# M2003 register map
File version: 1.0
Registers are 32-bit, read-write, reset 0x0 unless marked. A register's access mark holds for its fields unless they carry their own. Offsets are from the block's base; [hi:lo] are bit positions; {n}, {i} and the like mark numbered series; 'fields as' and 'values as' point back to an identical list.

## SYS — SYS Register Map
Base 0x40000000
0x00 SYS_PDID ro reset 0x200300 — Part Device Identification Number Register
  [31:0] PDID — Part Device Identification Number (Read Only). This register reflects device part number code. Software can read this register to identify which device is used.
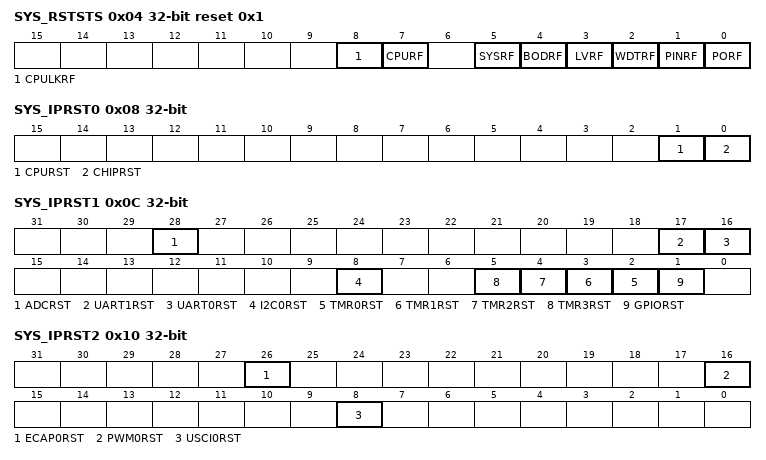
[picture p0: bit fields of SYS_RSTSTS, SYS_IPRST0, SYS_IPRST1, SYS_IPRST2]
0x04 SYS_RSTSTS reset 0x1 — System Reset Status Register
  [8] CPULKRF — CPU Lockup Reset Flag. The CPU Lockup reset flag is set by hardware if Cortex-M23 lockup happened. Note 1: Write 1 to clear this bit to 0. Note 2: When CPU lockup happened under ICE is connected, this flag will set to 1 but chip will not reset.
    0=No reset from CPU lockup happened; 1=The Cortex-M23 lockup happened and chip is reset
  [7] CPURF — CPU Reset Flag. The CPU reset flag is set by hardware if software writes CPURST (SYS_IPRST0[1]) 1 to reset the Cortex-M23 core and Flash Memory Controller (FMC). Note: Write 1 to clear this bit to 0.
    0=No reset from CPU; 1=The Cortex-M23 core and FMC are reset by software setting CPURST to 1
  [5] SYSRF — System Reset Flag. The system reset flag is set by the 'Reset Signal' from the Cortex-M23 core to indicate the previous reset source. Note: Write 1 to clear this bit to 0.
    0=No reset from the Cortex-M23; 1=The Cortex-M23 had issued the reset signal to reset the system by writing 1 to the bit SYSRESETREQ(AIRCR[2], Application Interrupt and Reset Control Register, address = 0xE000ED0C) in system control registers of Cortex-M23 core
  [4] BODRF — BOD Reset Flag. The BOD reset flag is set by the 'Reset Signal' from the Brown-out Detector to indicate the previous reset source, and BOD reset flag is not set in SPD mode when BOD reset occur. Note: Write 1 to clear this bit to 0.
    0=No reset from BOD; 1=The BOD had issued the reset signal to reset the system
  [3] LVRF — LVR Reset Flag. The LVR reset flag is set by the 'Reset Signal' from the Low Voltage Reset Controller to indicate the previous reset source, and LVR reset flag is not set in SPD mode when LVR reset occur. Note: Write 1 to clear this bit to 0.
    0=No reset from LVR; 1=The LVR controller had issued the reset signal to reset the system
  [2] WDTRF — WDT Reset Flag. The WDT reset flag is set by the 'Reset Signal' from the Watchdog Timer or Window Watchdog Timer to indicate the previous reset source. Note 1: Write 1 to clear this bit to 0. Note 2: Watchdog Timer register RSTF(WDT_CTL[2]) bit is set if the system has been reset by WDT time-out reset. Window Watchdog Timer register WWDTRF(WWDT_STATUS[1]) bit is set if the system has been reset by WWDT time-out reset.
    0=No reset from watchdog timer or window watchdog timer; 1=The watchdog timer or window watchdog timer had issued the reset signal to reset the system
  [1] PINRF — nRESET Pin Reset Flag. The nRESET pin reset flag is set by the 'Reset Signal' from the nRESET Pin to indicate the previous reset source. Note: Write 1 to clear this bit to 0.
    0=No reset from nRESET pin; 1=Pin nRESET had issued the reset signal to reset the system
  [0] PORF — POR Reset Flag. The POR reset flag is set by the 'Reset Signal' from the Power-on Reset (POR) Controller or bit CHIPRST (SYS_IPRST0[0]) to indicate the previous reset source. Note: Write 1 to clear this bit to 0.
    0=No reset from POR or CHIPRST; 1=Power-on Reset (POR) or CHIPRST had issued the reset signal to reset the system
0x08 SYS_IPRST0 — Peripheral Reset Control Register 0
  [1] CPURST — Processor Core One-shot Reset (Write Protect). Setting this bit will only reset the processor core and Flash Memory Controller(FMC), and this bit will automatically return to 0 after the 2 clock cycles. Note: This bit is write protected. Refer to the SYS_REGLCTL register.
    0=Processor core normal operation; 1=Processor core one-shot reset
  [0] CHIPRST — Chip One-shot Reset (Write Protect). Setting this bit will reset the whole chip, including Processor core and all peripherals, and this bit will automatically return to 0 after the 2 clock cycles. The CHIPRST is same as the POR reset, all the chip controllers is reset and the chip setting from Flash are also reload. About the difference between CHIPRST and SYSRESETREQ(AIRCR[2]), please refer to section 6.2.2. Note: This bit is write protected. Refer to the SYS_REGLCTL register.
    0=Chip normal operation; 1=Chip one-shot reset
0x0C SYS_IPRST1 — Peripheral Reset Control Register 1
  [28] ADCRST — ADC Controller Reset
    0=ADC controller normal operation; 1=ADC controller reset
  [17] UART1RST — UART1 Controller Reset
    0=UART1 controller normal operation; 1=UART1 controller reset
  [16] UART0RST — UART0 Controller Reset
    0=UART0 controller normal operation; 1=UART0 controller reset
  [8] I2C0RST — I2C0 Controller Reset
    0=I2C0 controller normal operation; 1=I2C0 controller reset
  [n+2] TMR{n}RST (n=0..3) — Timer{n} Controller Reset
    0=Timer{n} controller normal operation; 1=Timer{n} controller reset
  [1] GPIORST — GPIO Controller Reset
    0=GPIO controller normal operation; 1=GPIO controller reset
0x10 SYS_IPRST2 — Peripheral Reset Control Register 2
  [26] ECAP0RST — ECAP0 Controller Reset
    0=ECAP0 controller normal operation; 1=ECAP0 controller reset
  [16] PWM0RST — PWM0 Controller Reset
    0=PWM0 controller normal operation; 1=PWM0 controller reset
  [8] USCI0RST — USCI0 Controller Reset
    0=USCI0 controller normal operation; 1=USCI0 controller reset
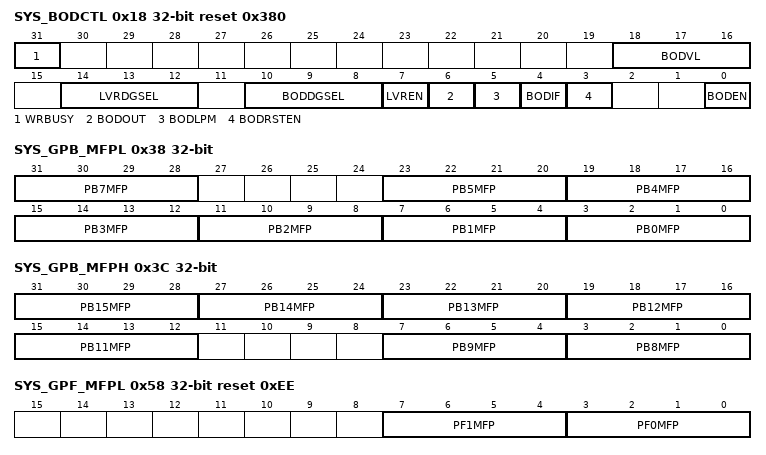
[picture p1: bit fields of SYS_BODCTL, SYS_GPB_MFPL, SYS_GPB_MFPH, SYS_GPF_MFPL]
0x18 SYS_BODCTL reset 0x380 (reset mask 0xFFF0FFF0) — Brown-out Detector Control Register
  [31] WRBUSY ro — Write Busy Flag (Read Only). If SYS_BODCTL is written, this bit is asserted automatically by hardware, and is de-asserted when write procedure is finished.
    0=SYS_BODCTL register is ready for write operation, and indicates LVR and BOD already stable, system cannot detect LVR and BOD event when this bit is not de-asserted; 1=SYS_BODCTL register is busy on the last write operation. Other write operations are ignored
  [18:16] BODVL — Brown-out Detector Threshold Voltage Selection (Write Protect). The default value is set by Flash controller user configuration register CBOV (CONFIG0 [23:21]). Note: These bits are write protected. Refer to the SYS_REGLCTL register.
    0=Brown-out Detector threshold voltage is 2.2V; 1=Brown-out Detector threshold voltage is 2.2V; 2=Brown-out Detector threshold voltage is 2.7V; 3=Brown-out Detector threshold voltage is 2.7V; 4=Brown-out Detector threshold voltage is 3.7V; 5=Brown-out Detector threshold voltage is 3.7V; 6=Brown-out Detector threshold voltage is 4.4V; 7=Brown-out Detector threshold voltage is 4.4V
  [14:12] LVRDGSEL — LVR Output De-glitch Time Select (Write Protect). Note: These bits are write protected. Refer to the SYS_REGLCTL register.
    0=Without de-glitch function; 1=4 system clock (HCLK); 2=8 system clock (HCLK); 3=16 system clock (HCLK); 4=32 system clock (HCLK); 5=64 system clock (HCLK); 6=128 system clock (HCLK); 7=256 system clock (HCLK)
  [10:8] BODDGSEL — Brown-out Detector Output De-glitch Time Select (Write Protect). Note: These bits are write protected. Refer to the SYS_REGLCTL register.
    0=BOD output is sampled by LIRC clock; 1=4 system clock (HCLK); 2=8 system clock (HCLK); 3=16 system clock (HCLK); 4=32 system clock (HCLK); 5=64 system clock (HCLK); 6=128 system clock (HCLK); 7=256 system clock (HCLK)
  [7] LVREN — Low Voltage Reset Enable Bit (Write Protect). The LVR function resets the chip when the input power voltage is lower than LVR circuit setting. LVR function is enabled by default. Note 1: After enabling the bit, the LVR function will be active with 200us delay for LVR output stable (default). Note 2: This bit is write protected. Refer to the SYS_REGLCTL register.
    0=Low Voltage Reset function Disabled; 1=Low Voltage Reset function Enabled
  [6] BODOUT ro — Brown-out Detector Output Status (Read Only). It means the detected voltage is lower than BODVL setting. If the BODEN is 0, BOD function disabled, this bit always responds 0.
    0=Brown-out Detector output status is 0; 1=Brown-out Detector output status is 1
  [5] BODLPM — Brown-out Detector Low Power Mode (Write Protect). Note 1: The BOD consumes about 100uA in normal mode, the low power mode can reduce the current to about 1/10 but slow the BOD response. Note 2: This bit is write protected. Refer to the SYS_REGLCTL register.
    0=BOD operate in normal mode (default); 1=BOD Low Power mode Enabled
  [4] BODIF — Brown-out Detector Interrupt Flag. Note: Write 1 to clear this bit to 0.
    0=Brown-out Detector does not detect any voltage draft at VDD down through or up through the voltage of BODVL setting; 1=When Brown-out Detector detects the VDD is dropped down through the voltage of BODVL setting or the VDD is raised up through the voltage of BODVL setting, this bit is set to 1 and the brown-out interrupt is requested if brown-out interrupt is enabled
  [3] BODRSTEN — Brown-out Reset Enable Bit (Write Protect). The default value is set by Flash controller user configuration register CBORST(CONFIG0[20]) bit. Note 1: When the Brown-out Detector function is enabled (BODEN high) and BOD reset function is enabled (BODRSTEN high), BOD will assert a signal to reset chip when the detected voltage is lower than the threshold (BODOUT high). When the BOD function is enabled (BODEN high) and BOD interrupt function is enabled (BODRSTEN low), BOD will assert an interrupt if AVDD is lower than BODVL, BOD interrupt will keep till the BODIF set to 0. BOD interrupt can be blocked by disabling the NVIC BOD interrupt or disabling BOD function (setting BODEN low). Note 2: This bit is write protected. Refer to the SYS_REGLCTL register.
    0=Brown-out 'INTERRUPT' function Enabled; 1=Brown-out 'RESET' function Enabled
  [0] BODEN — Brown-out Detector Enable Bit (Write Protect). The default value is set by Flash controller user configuration register CBODEN (CONFIG0 [23]). Note: This bit is write protected. Refer to the SYS_REGLCTL register.
    0=Brown-out Detector function Disabled; 1=Brown-out Detector function Enabled
0x24 SYS_PORCTL0 (reset mask 0xFFFFFF00) — Power-on Reset Controller Register 0
  [15:0] PORMASK — Power-on Reset Mask Enable Bit (Write Protect). When powered on, the POR circuit generates a reset signal to reset the whole chip function, but noise on the power may cause the POR active again. User can mask internal POR signal to avoid unpredictable noise to cause chip reset by writing 0x5AA5 to this field. The POR function will be active again when this field is set to another value or chip is reset by other reset source, including: nRESET, Watchdog, LVR reset, BOD reset, ICE reset command and the software-chip reset function. Note: These bits are write protected. Refer to the SYS_REGLCTL register.
0x38 SYS_GPB_MFPL — GPIOB Low Byte Multiple Function Control Register
  [31:28] PB7MFP — PB.7 Multi-function Pin Selection
  [23:20] PB5MFP — PB.5 Multi-function Pin Selection
  [19:16] PB4MFP — PB.4 Multi-function Pin Selection
  [15:12] PB3MFP — PB.3 Multi-function Pin Selection
  [11:8] PB2MFP — PB.2 Multi-function Pin Selection
  [7:4] PB1MFP — PB.1 Multi-function Pin Selection
  [3:0] PB0MFP — PB.0 Multi-function Pin Selection
0x3C SYS_GPB_MFPH — GPIOB High Byte Multiple Function Control Register
  [31:28] PB15MFP — PB.15 Multi-function Pin Selection
  [27:24] PB14MFP — PB.14 Multi-function Pin Selection
  [23:20] PB13MFP — PB.13 Multi-function Pin Selection
  [19:16] PB12MFP — PB.12 Multi-function Pin Selection
  [15:12] PB11MFP — PB.11 Multi-function Pin Selection
  [7:4] PB9MFP — PB.9 Multi-function Pin Selection
  [3:0] PB8MFP — PB.8 Multi-function Pin Selection
0x44 SYS_GPC_MFPH — GPIOC High Byte Multiple Function Control Register
  [27:24] PC14MFP — PC.14 Multi-function Pin Selection
0x54 SYS_GPE_MFPH — GPIOE High Byte Multiple Function Control Register
  [31:28] PE15MFP — PE.15 Multi-function Pin Selection
0x58 SYS_GPF_MFPL reset 0xEE — GPIOF Low Byte Multiple Function Control Register
  [7:4] PF1MFP — PF.1 Multi-function Pin Selection
  [3:0] PF0MFP — PF.0 Multi-function Pin Selection
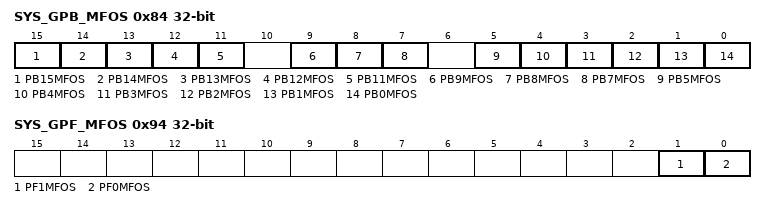
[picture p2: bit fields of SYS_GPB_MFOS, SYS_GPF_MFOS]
0x84 SYS_GPB_MFOS — GPIOB Multiple Function Output Select Register
  [all] fields
    0=Multiple function pin output mode type is Push-pull mode; 1=Multiple function pin output mode type is Open-drain mode
  [15] PB15MFOS — PB.15 Multiple Function Pin Output Mode Select. This bit used to select multiple function pin output mode type for PB.15 pin.
  [14] PB14MFOS — PB.14 Multiple Function Pin Output Mode Select. This bit used to select multiple function pin output mode type for PB.14 pin.
  [13] PB13MFOS — PB.13 Multiple Function Pin Output Mode Select. This bit used to select multiple function pin output mode type for PB.13 pin.
  [12] PB12MFOS — PB.12 Multiple Function Pin Output Mode Select. This bit used to select multiple function pin output mode type for PB.12 pin.
  [11] PB11MFOS — PB.11 Multiple Function Pin Output Mode Select. This bit used to select multiple function pin output mode type for PB.11 pin.
  [9] PB9MFOS — PB.9 Multiple Function Pin Output Mode Select. This bit used to select multiple function pin output mode type for PB.9 pin.
  [8] PB8MFOS — PB.8 Multiple Function Pin Output Mode Select. This bit used to select multiple function pin output mode type for PB.8 pin.
  [7] PB7MFOS — PB.7 Multiple Function Pin Output Mode Select. This bit used to select multiple function pin output mode type for PB.7 pin.
  [5] PB5MFOS — PB.5 Multiple Function Pin Output Mode Select. This bit used to select multiple function pin output mode type for PB.5 pin.
  [4] PB4MFOS — PB.4 Multiple Function Pin Output Mode Select. This bit used to select multiple function pin output mode type for PB.4 pin.
  [3] PB3MFOS — PB.3 Multiple Function Pin Output Mode Select. This bit used to select multiple function pin output mode type for PB.3 pin.
  [2] PB2MFOS — PB.2 Multiple Function Pin Output Mode Select. This bit used to select multiple function pin output mode type for PB.2 pin.
  [1] PB1MFOS — PB.1 Multiple Function Pin Output Mode Select. This bit used to select multiple function pin output mode type for PB.1 pin.
  [0] PB0MFOS — PB.0 Multiple Function Pin Output Mode Select. This bit used to select multiple function pin output mode type for PB.0 pin.
0x88 SYS_GPC_MFOS — GPIOC Multiple Function Output Select Register
  [14] PC14MFOS — PC.14 Multiple Function Pin Output Mode Select. This bit used to select multiple function pin output mode type for PC.14 pin.
    values as the fields of SYS_GPB_MFOS
0x94 SYS_GPF_MFOS — GPIOF Multiple Function Output Select Register
  [1] PF1MFOS — PF.1 Multiple Function Pin Output Mode Select. This bit used to select multiple function pin output mode type for PF.1 pin.
    values as the fields of SYS_GPB_MFOS
  [0] PF0MFOS — PF.0 Multiple Function Pin Output Mode Select. This bit used to select multiple function pin output mode type for PF.0 pin.
    values as the fields of SYS_GPB_MFOS
0x100 SYS_REGLCTL — Register Lock Control Register
  [7:0] REGLCTL — Register Lock Control Code. Some registers have write-protection function. Writing these registers have to disable the protected function by writing the sequence value '59h', '16h', '88h' to this field. After this sequence is completed, the REGLCTL bit will be set to 1 and write-protection registers can be normal write. REGLCTL[0]. Register Lock Control Disable Index
    0=Write-protection Enabled for writing protected registers. Any write to the protected register is ignored; 1=Write-protection Disabled for writing protected registers
0x1D8 SYS_CPUCFG — CPU General Configuration Register
  [0] INTRTEN — CPU Interrupt Realtime Enable Bit. When this bit is 0, the latency of CPU entering interrupt service routine (ISR) will be various but shorter. When this bit is 1, the latency of CPU entering ISR will be kept constant.
    0=CPU Interrupt Realtime Disabled; 1=CPU Interrupt Realtime Enabled
0x1EC SYS_PORCTL1 (reset mask 0xFFFFFF00) — Power-on Reset Controller Register 1
  [15:0] POROFF — Power-on Reset Enable Bit (Write Protect). When powered on, the POR circuit generates a reset signal to reset the whole chip function, but noise on the power may cause the POR active again. User can disable internal POR circuit to avoid unpredictable noise to cause chip reset by writing 0x5AA5 to this field. The POR function will be active again when this field is set to another value or chip is reset by other reset source, including: nRESET, Watchdog, LVR reset, BOD reset, ICE reset command and the software-chip reset function. Note: These bits are write protected. Refer to the SYS_REGLCTL register.
